# ATxmega16E5 device description
Architecture: AVR8_XMEGA; Family: AVR XMEGA
Registers are 8-bit, access not given, no defined reset value unless marked. A register's access mark holds for its fields unless they carry their own. Offsets are from the block's base; [hi:lo] are bit positions; {n}, {i} and the like mark numbered series; 'fields as' and 'values as' point back to an identical list.

## FAULT — Fault Extension
Instances: FAULTC4 0x880, FAULTC5 0x890
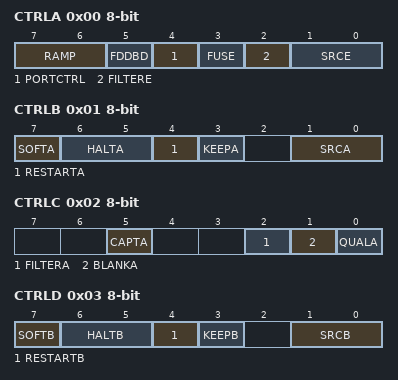
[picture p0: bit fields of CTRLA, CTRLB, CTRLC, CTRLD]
0x00 CTRLA — Control A Register
  [7:6] RAMP — Ramp Mode Selection
    0=Normal Mode; 2=RAMP2 Mode
  [5] FDDBD — Fault on Debug Break Detection
  [4] PORTCTRL — Port Control Mode
  [3] FUSE — Fuse State
  [2] FILTERE — Fault E Digital Filter Selection
  [1:0] SRCE — Fault E Input selection
    0=DISABLE (Fault Protection Disabled); 1=CHN (Event Channel n); 2=CHN1 (Event Channel n+1); 3=CHN2 (Event Channel n+2)
0x01 CTRLB — Control B Register
  [7] SOFTA — Fault A Software Mode
  [6:5] HALTA — Fault A Halt Action
    0=DISABLE (Halt Action Disabled); 1=HW (Hardware Halt Action); 2=SW (Software Halt Action)
  [4] RESTARTA — Fault A Restart Action
  [3] KEEPA — Fault A Keep Action
  [1:0] SRCA — Fault A Source Selection
    0=DISABLE (Fault A Disabled); 1=CHN (Event Channel n); 2=CHN1 (Event Channel n+1); 3=LINK (Fault A linked to Fault B State from previous cycle)
0x02 CTRLC — Control C Register
  [5] CAPTA — Fault A Capture
  [2] FILTERA — Fault A Digital Filter Selection
  [1] BLANKA — Fault A Blanking
  [0] QUALA — Fault A Qualification
0x03 CTRLD — Control D Register
  [7] SOFTB — Fault B Software Mode
  [6:5] HALTB — Fault B Halt Action
    values as CTRLB.HALTA
  [4] RESTARTB — Fault B Restart Action
  [3] KEEPB — Fault B Keep Action
  [1:0] SRCB — Fault B Source Selection
    0=DISABLE (Fault B disabled); 1=CHN (Event Channel n); 2=CHN1 (Event Channel n+1); 3=LINK (Fault B linked to Fault A State from previous cycle)
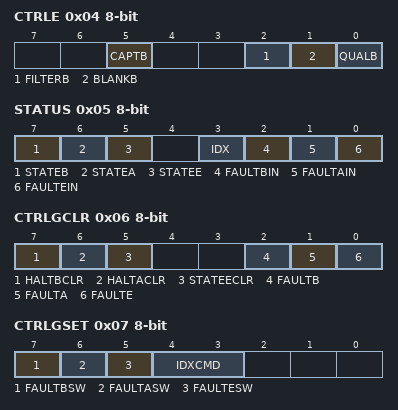
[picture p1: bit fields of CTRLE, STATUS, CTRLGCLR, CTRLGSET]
0x04 CTRLE — Control E Register
  [5] CAPTB — Fault B Capture
  [2] FILTERB — Fault B Digital Filter Selection
  [1] BLANKB — Fault B Blanking
  [0] QUALB — Fault B Qualification
0x05 STATUS
  [7] STATEB — Fault B State
  [6] STATEA — Fault A State
  [5] STATEE — Fault E State
  [3] IDX — Channel Index Flag
  [2] FAULTBIN — Fault B Flag
  [1] FAULTAIN — Fault A Flag
  [0] FAULTEIN — Fault E Flag
0x06 CTRLGCLR — Control Register G Clear
  [7] HALTBCLR — State B Clear
  [6] HALTACLR — State A Clear
  [5] STATEECLR — State E Clear
  [2] FAULTB — Fault B Flag
  [1] FAULTA — Fault A Flag
  [0] FAULTE — Fault E Flag
0x07 CTRLGSET — Control Register G set
  [7] FAULTBSW — Software Fault B
  [6] FAULTASW — Software Fault A
  [5] FAULTESW — Software Fault E
  [4:3] IDXCMD — Channel index Command
    0=DISABLE (Command Disabled); 1=SET (Force Cycle B in Next Cycle); 2=CLEAR (Force Cycle A in Next Cycle); 3=HOLD (Hold Current Cycle Index in Next Cycle)

## WEX — Waveform Extension
Instances: WEXC 0x8A0
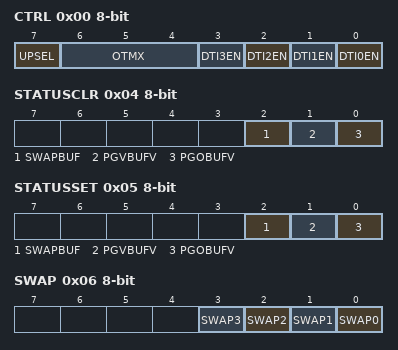
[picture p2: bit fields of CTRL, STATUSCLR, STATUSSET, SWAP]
0x00 CTRL — Control Register
  [7] UPSEL — Update Source Selection
  [6:4] OTMX — Output Matrix
    0=DEFAULT (Default Output Matrix Mode); 1=FIRST (First Output matrix Mode); 2=SECOND (Second Output matrix Mode); 3=THIRD (Third Output matrix Mode); 4=FOURTH (Fourth Output matrix Mode)
  [n] DTI{n}EN (n=0..3) — Dead-Time Insertion Generator {n} Enable
0x01 DTBOTH — Dead-time Concurrent Write to Both Sides Register
0x02 DTLS — Dead-time Low Side Register
0x03 DTHS — Dead-time High Side Register
0x04 STATUSCLR — Status Clear Register
  [2] SWAPBUF — Swap Buffer Valid
  [1] PGVBUFV — Pattern Generator Value Buffer Valid
  [0] PGOBUFV — Pattern Generator Overwrite Buffer Valid
0x05 STATUSSET
  fields as STATUSCLR
0x06 SWAP
  [n] SWAP{n} (n=0..3) — Swap DTI output pair {n}
0x07 PGO — Pattern Generation Override Register
0x08 PGV — Pattern Generation Value Register
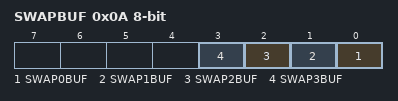
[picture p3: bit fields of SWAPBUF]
0x0A SWAPBUF — Dead Time Low Side Buffer
  [n] SWAP{n}BUF (n=0..3) — Swap DTI output pair {n}
0x0B PGOBUF — Pattern Generation Overwrite Buffer Register
0x0C PGVBUF — Pattern Generation Value Buffer Register
0x0F OUTOVDIS — Output Override Disable Register
